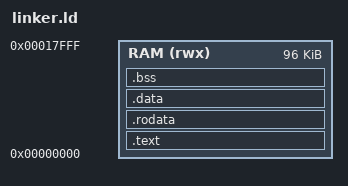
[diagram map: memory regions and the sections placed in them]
ENTRY(_start)

MEMORY { RAM (rwx) : ORIGIN = 0x00000000, LENGTH = 96K }

SECTIONS {
    .text : { KEEP(*(.text.start)) *(.text*) } > RAM
    .rodata : { *(.rodata*) } > RAM
    .data : { *(.data*) } > RAM
    .bss (NOLOAD) : {
        __bss_start = .;
        *(.bss*) *(COMMON)
        __bss_end = .;
    } > RAM
    __stack_top = ORIGIN(RAM) + LENGTH(RAM);
    ASSERT(__stack_top >= . + 256, "RAM image leaves less than 256 bytes for stack")
}
